VERSION ""

NS_ :

BS_:

BU_:
VAL_TABLE_ TAB_BattSimRemoteControl 3 "signal invalid" 2 "Remote-Control-Mode" 1 "Standalone-Mode" 0 "no signal" ;
VAL_TABLE_ TAB_BattSimOutputControl 3 "signal invalid" 2 "enable all outputs" 1 "disable all output" 0 "no signal" ;
VAL_TABLE_ TAB_BattSimOutputStatus 3 "signal invalid" 2 "Output enabled" 1 "Output disabled" 0 "no signal" ;
VAL_TABLE_ TAB_BattSimStatus 7 "signal invalid" 6 "reserved" 5 "FAIL" 4 "ON_DynamicCellSim" 3 "ON_RemoteControl" 2 "ON_Standalone" 1 "STANDBY" 0 "no signal" ;

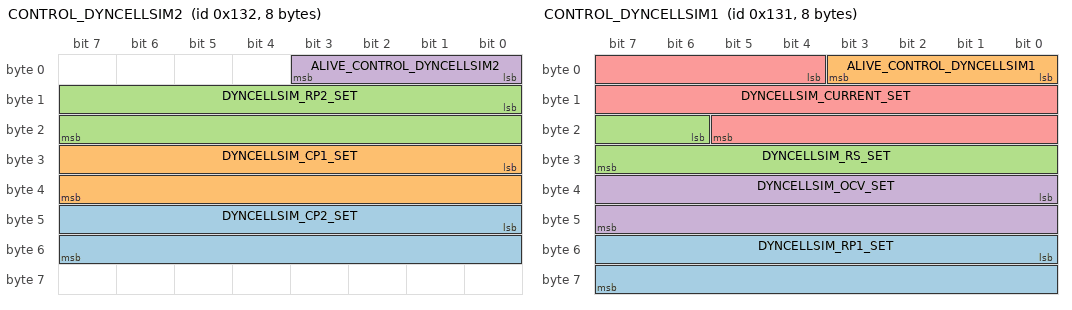
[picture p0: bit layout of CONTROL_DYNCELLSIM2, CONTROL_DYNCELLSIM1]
BO_ 306 CONTROL_DYNCELLSIM2: 8 Vector__XXX
 SG_ DYNCELLSIM_CP2_SET : 40|16@1+ (10,0) [0|655350] "F" Vector__XXX
 SG_ DYNCELLSIM_CP1_SET : 24|16@1+ (10,0) [0|655350] "F" Vector__XXX
 SG_ DYNCELLSIM_RP2_SET : 8|16@1+ (0.0001,0) [0|6.5535] "Ohm" Vector__XXX
 SG_ ALIVE_CONTROL_DYNCELLSIM2 : 0|4@1+ (1,0) [0|15] "" Vector__XXX

BO_ 305 CONTROL_DYNCELLSIM1: 8 Vector__XXX
 SG_ DYNCELLSIM_RP1_SET : 48|16@1+ (0.0001,0) [0|6.5535] "Ohm" Vector__XXX
 SG_ ALIVE_CONTROL_DYNCELLSIM1 : 0|4@1+ (1,0) [0|15] "" Vector__XXX
 SG_ DYNCELLSIM_RS_SET : 22|10@1+ (0.0001,0) [0|0.1023] "Ohm" Vector__XXX
 SG_ DYNCELLSIM_OCV_SET : 32|16@1+ (0.0001,0) [0|6.5535] "V" Vector__XXX
 SG_ DYNCELLSIM_CURRENT_SET : 4|18@1- (0.001,0) [-131.072|131.071] "A" Vector__XXX

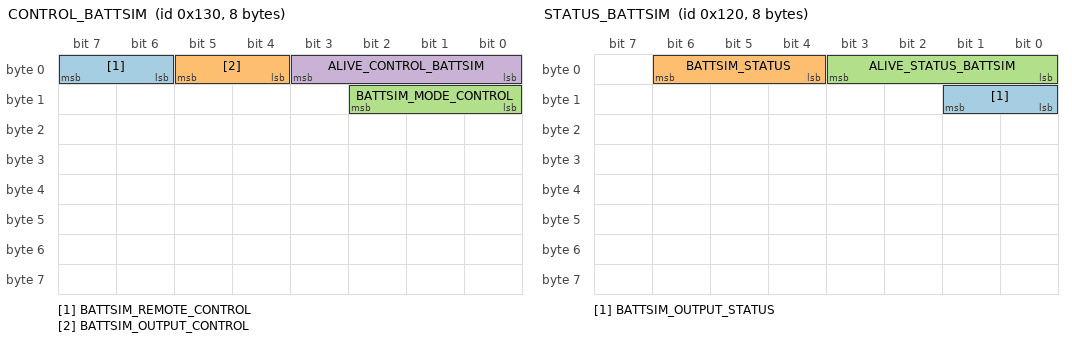
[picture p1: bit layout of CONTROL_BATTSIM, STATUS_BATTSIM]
BO_ 304 CONTROL_BATTSIM: 8 Vector__XXX
 SG_ BATTSIM_REMOTE_CONTROL : 6|2@1+ (1,0) [0|3] "" Vector__XXX
 SG_ BATTSIM_OUTPUT_CONTROL : 4|2@1+ (1,0) [0|3] "" Vector__XXX
 SG_ BATTSIM_MODE_CONTROL : 8|3@1+ (1,0) [0|7] "" Vector__XXX
 SG_ ALIVE_CONTROL_BATTSIM : 0|4@1+ (1,0) [0|15] "" Vector__XXX

BO_ 288 STATUS_BATTSIM: 8 Vector__XXX
 SG_ BATTSIM_OUTPUT_STATUS : 8|2@1+ (1,0) [0|3] "" Vector__XXX
 SG_ BATTSIM_STATUS : 4|3@1+ (1,0) [0|7] "" Vector__XXX
 SG_ ALIVE_STATUS_BATTSIM : 0|4@1+ (1,0) [0|15] "" Vector__XXX

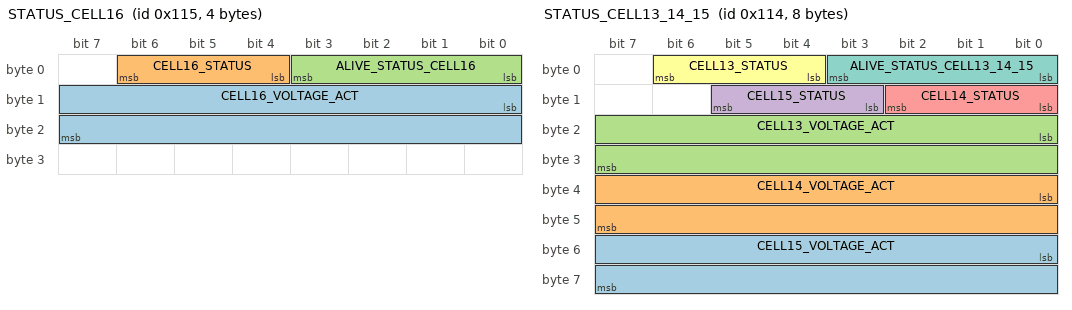
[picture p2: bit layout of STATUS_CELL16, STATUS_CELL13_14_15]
BO_ 277 STATUS_CELL16: 4 Vector__XXX
 SG_ CELL16_VOLTAGE_ACT : 8|16@1+ (0.0001,0) [0|6.5535] "V" Vector__XXX
 SG_ CELL16_STATUS : 4|3@1+ (1,0) [0|3] "" Vector__XXX
 SG_ ALIVE_STATUS_CELL16 : 0|4@1+ (1,0) [0|15] "" Vector__XXX

BO_ 276 STATUS_CELL13_14_15: 8 Vector__XXX
 SG_ CELL15_VOLTAGE_ACT : 48|16@1+ (0.0001,0) [0|6.5535] "V" Vector__XXX
 SG_ CELL14_VOLTAGE_ACT : 32|16@1+ (0.0001,0) [0|6.5535] "V" Vector__XXX
 SG_ CELL13_VOLTAGE_ACT : 16|16@1+ (0.0001,0) [0|6.5535] "V" Vector__XXX
 SG_ CELL15_STATUS : 11|3@1+ (1,0) [0|3] "" Vector__XXX
 SG_ CELL14_STATUS : 8|3@1+ (1,0) [0|3] "" Vector__XXX
 SG_ CELL13_STATUS : 4|3@1+ (1,0) [0|3] "" Vector__XXX
 SG_ ALIVE_STATUS_CELL13_14_15 : 0|4@1+ (1,0) [0|15] "" Vector__XXX

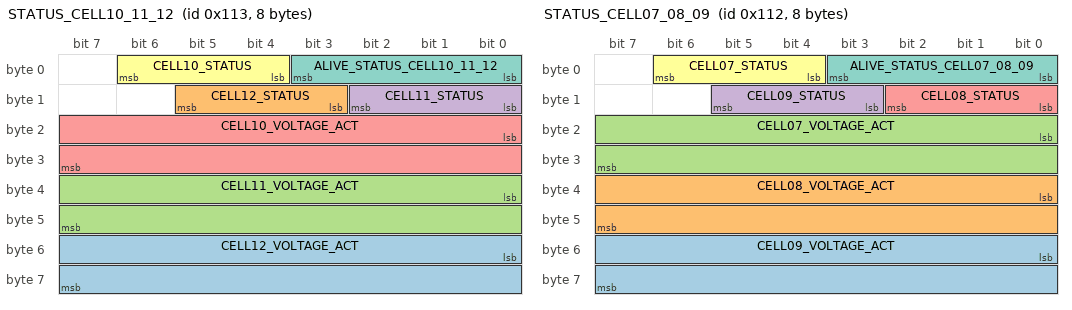
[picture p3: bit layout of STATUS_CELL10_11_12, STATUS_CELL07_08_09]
BO_ 275 STATUS_CELL10_11_12: 8 Vector__XXX
 SG_ CELL12_VOLTAGE_ACT : 48|16@1+ (0.0001,0) [0|6.5535] "V" Vector__XXX
 SG_ CELL12_STATUS : 11|3@1+ (1,0) [0|3] "" Vector__XXX
 SG_ CELL11_VOLTAGE_ACT : 32|16@1+ (0.0001,0) [0|6.5535] "V" Vector__XXX
 SG_ CELL11_STATUS : 8|3@1+ (1,0) [0|3] "" Vector__XXX
 SG_ CELL10_VOLTAGE_ACT : 16|16@1+ (0.0001,0) [0|6.5535] "V" Vector__XXX
 SG_ CELL10_STATUS : 4|3@1+ (1,0) [0|3] "" Vector__XXX
 SG_ ALIVE_STATUS_CELL10_11_12 : 0|4@1+ (1,0) [0|15] "" Vector__XXX

BO_ 274 STATUS_CELL07_08_09: 8 Vector__XXX
 SG_ CELL09_VOLTAGE_ACT : 48|16@1+ (0.0001,0) [0|6.5535] "V" Vector__XXX
 SG_ CELL08_VOLTAGE_ACT : 32|16@1+ (0.0001,0) [0|6.5535] "V" Vector__XXX
 SG_ CELL07_VOLTAGE_ACT : 16|16@1+ (0.0001,0) [0|6.5535] "V" Vector__XXX
 SG_ CELL09_STATUS : 11|3@1+ (1,0) [0|3] "" Vector__XXX
 SG_ CELL08_STATUS : 8|3@1+ (1,0) [0|3] "" Vector__XXX
 SG_ CELL07_STATUS : 4|3@1+ (1,0) [0|3] "" Vector__XXX
 SG_ ALIVE_STATUS_CELL07_08_09 : 0|4@1+ (1,0) [0|15] "" Vector__XXX

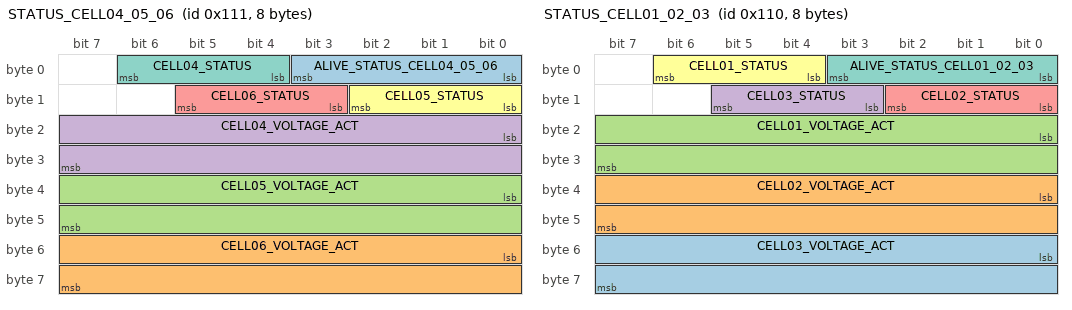
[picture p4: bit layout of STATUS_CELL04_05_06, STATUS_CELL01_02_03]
BO_ 273 STATUS_CELL04_05_06: 8 Vector__XXX
 SG_ ALIVE_STATUS_CELL04_05_06 : 0|4@1+ (1,0) [0|15] "" Vector__XXX
 SG_ CELL06_VOLTAGE_ACT : 48|16@1+ (0.0001,0) [0|6.5535] "V" Vector__XXX
 SG_ CELL05_VOLTAGE_ACT : 32|16@1+ (0.0001,0) [0|6.5535] "V" Vector__XXX
 SG_ CELL04_VOLTAGE_ACT : 16|16@1+ (0.0001,0) [0|6.5535] "V" Vector__XXX
 SG_ CELL06_STATUS : 11|3@1+ (1,0) [0|3] "" Vector__XXX
 SG_ CELL05_STATUS : 8|3@1+ (1,0) [0|3] "" Vector__XXX
 SG_ CELL04_STATUS : 4|3@1+ (1,0) [0|3] "" Vector__XXX

BO_ 272 STATUS_CELL01_02_03: 8 Vector__XXX
 SG_ CELL03_VOLTAGE_ACT : 48|16@1+ (0.0001,0) [0|6.5535] "V" Vector__XXX
 SG_ CELL02_VOLTAGE_ACT : 32|16@1+ (0.0001,0) [0|6.5535] "V" Vector__XXX
 SG_ CELL01_VOLTAGE_ACT : 16|16@1+ (0.0001,0) [0|6.5535] "V" Vector__XXX
 SG_ CELL03_STATUS : 11|3@1+ (1,0) [0|3] "" Vector__XXX
 SG_ CELL02_STATUS : 8|3@1+ (1,0) [0|3] "" Vector__XXX
 SG_ CELL01_STATUS : 4|3@1+ (1,0) [0|3] "" Vector__XXX
 SG_ ALIVE_STATUS_CELL01_02_03 : 0|4@1+ (1,0) [0|15] "" Vector__XXX

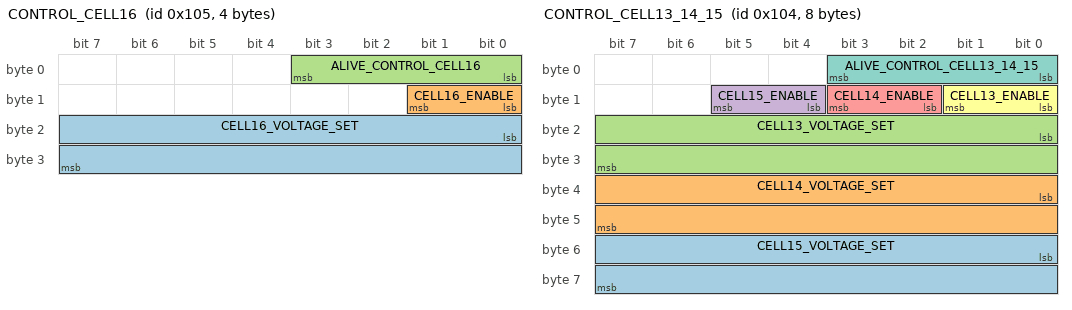
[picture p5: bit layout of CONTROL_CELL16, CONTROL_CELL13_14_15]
BO_ 261 CONTROL_CELL16: 4 Vector__XXX
 SG_ CELL16_VOLTAGE_SET : 16|16@1+ (0.0001,0) [0|6.5535] "V" Vector__XXX
 SG_ CELL16_ENABLE : 8|2@1+ (1,0) [0|3] "" Vector__XXX
 SG_ ALIVE_CONTROL_CELL16 : 0|4@1+ (1,0) [0|15] "" Vector__XXX

BO_ 260 CONTROL_CELL13_14_15: 8 Vector__XXX
 SG_ CELL15_VOLTAGE_SET : 48|16@1+ (0.0001,0) [0|6.5535] "V" Vector__XXX
 SG_ CELL14_VOLTAGE_SET : 32|16@1+ (0.0001,0) [0|6.5535] "V" Vector__XXX
 SG_ CELL13_VOLTAGE_SET : 16|16@1+ (0.0001,0) [0|6.5535] "V" Vector__XXX
 SG_ CELL15_ENABLE : 12|2@1+ (1,0) [0|3] "" Vector__XXX
 SG_ CELL14_ENABLE : 10|2@1+ (1,0) [0|3] "" Vector__XXX
 SG_ CELL13_ENABLE : 8|2@1+ (1,0) [0|3] "" Vector__XXX
 SG_ ALIVE_CONTROL_CELL13_14_15 : 0|4@1+ (1,0) [0|15] "" Vector__XXX

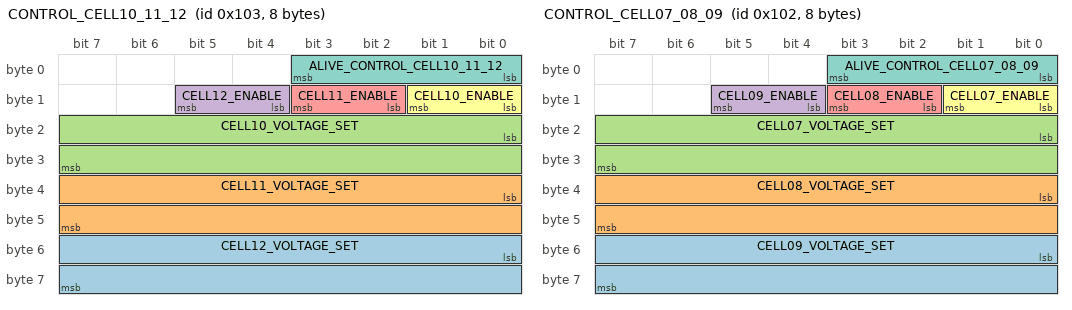
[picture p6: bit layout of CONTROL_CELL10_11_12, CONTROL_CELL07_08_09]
BO_ 259 CONTROL_CELL10_11_12: 8 Vector__XXX
 SG_ CELL12_VOLTAGE_SET : 48|16@1+ (0.0001,0) [0|6.5535] "V" Vector__XXX
 SG_ CELL11_VOLTAGE_SET : 32|16@1+ (0.0001,0) [0|6.5535] "V" Vector__XXX
 SG_ CELL10_VOLTAGE_SET : 16|16@1+ (0.0001,0) [0|6.5535] "V" Vector__XXX
 SG_ CELL12_ENABLE : 12|2@1+ (1,0) [0|3] "" Vector__XXX
 SG_ CELL11_ENABLE : 10|2@1+ (1,0) [0|3] "" Vector__XXX
 SG_ CELL10_ENABLE : 8|2@1+ (1,0) [0|3] "" Vector__XXX
 SG_ ALIVE_CONTROL_CELL10_11_12 : 0|4@1+ (1,0) [0|15] "" Vector__XXX

BO_ 258 CONTROL_CELL07_08_09: 8 Vector__XXX
 SG_ CELL09_VOLTAGE_SET : 48|16@1+ (0.0001,0) [0|6.5535] "V" Vector__XXX
 SG_ CELL08_VOLTAGE_SET : 32|16@1+ (0.0001,0) [0|6.5535] "V" Vector__XXX
 SG_ CELL07_VOLTAGE_SET : 16|16@1+ (0.0001,0) [0|6.5535] "V" Vector__XXX
 SG_ CELL09_ENABLE : 12|2@1+ (1,0) [0|3] "" Vector__XXX
 SG_ CELL08_ENABLE : 10|2@1+ (1,0) [0|3] "" Vector__XXX
 SG_ CELL07_ENABLE : 8|2@1+ (1,0) [0|3] "" Vector__XXX
 SG_ ALIVE_CONTROL_CELL07_08_09 : 0|4@1+ (1,0) [0|15] "" Vector__XXX

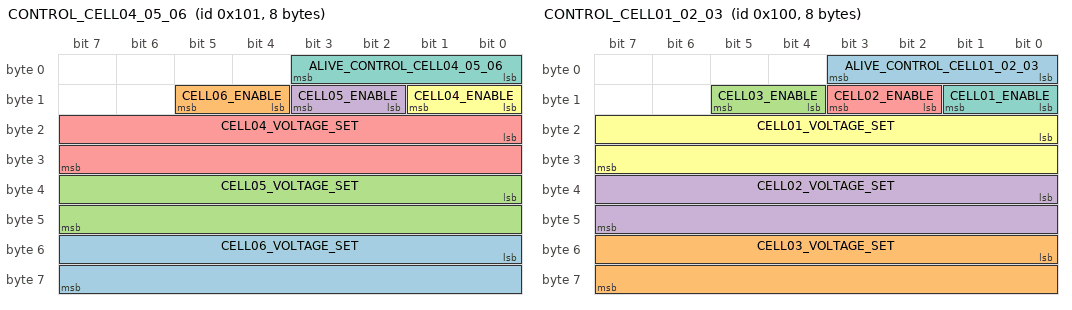
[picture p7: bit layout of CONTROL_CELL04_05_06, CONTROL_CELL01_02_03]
BO_ 257 CONTROL_CELL04_05_06: 8 Vector__XXX
 SG_ CELL06_VOLTAGE_SET : 48|16@1+ (0.0001,0) [0|6.5535] "V" Vector__XXX
 SG_ CELL06_ENABLE : 12|2@1+ (1,0) [0|3] "" Vector__XXX
 SG_ CELL05_VOLTAGE_SET : 32|16@1+ (0.0001,0) [0|6.5535] "V" Vector__XXX
 SG_ CELL05_ENABLE : 10|2@1+ (1,0) [0|3] "" Vector__XXX
 SG_ CELL04_VOLTAGE_SET : 16|16@1+ (0.0001,0) [0|6.5535] "V" Vector__XXX
 SG_ CELL04_ENABLE : 8|2@1+ (1,0) [0|3] "" Vector__XXX
 SG_ ALIVE_CONTROL_CELL04_05_06 : 0|4@1+ (1,0) [0|15] "" Vector__XXX

BO_ 256 CONTROL_CELL01_02_03: 8 Vector__XXX
 SG_ ALIVE_CONTROL_CELL01_02_03 : 0|4@1+ (1,0) [0|15] "" Vector__XXX
 SG_ CELL03_VOLTAGE_SET : 48|16@1+ (0.0001,0) [0|6.5535] "V" Vector__XXX
 SG_ CELL03_ENABLE : 12|2@1+ (1,0) [0|3] "" Vector__XXX
 SG_ CELL02_VOLTAGE_SET : 32|16@1+ (0.0001,0) [0|6.5535] "V" Vector__XXX
 SG_ CELL02_ENABLE : 10|2@1+ (1,0) [0|3] "" Vector__XXX
 SG_ CELL01_VOLTAGE_SET : 16|16@1+ (0.0001,0) [0|6.5535] "V" Vector__XXX
 SG_ CELL01_ENABLE : 8|2@1+ (1,0) [0|3] "" Vector__XXX

CM_ SG_ 305 DYNCELLSIM_OCV_SET "Zellspannungs-Vorgabe";
CM_ SG_ 277 CELL16_VOLTAGE_ACT "gemessene Zellspannung 16";
CM_ SG_ 276 CELL15_VOLTAGE_ACT "gemessene Zellspannung 15";
CM_ SG_ 276 CELL14_VOLTAGE_ACT "gemessene Zellspannung 14";
CM_ SG_ 276 CELL13_VOLTAGE_ACT "gemessene Zellspannung 13";
CM_ SG_ 275 CELL12_VOLTAGE_ACT "gemessene Zellspannung 12";
CM_ SG_ 275 CELL11_VOLTAGE_ACT "gemessene Zellspannung 11";
CM_ SG_ 275 CELL10_VOLTAGE_ACT "gemessene Zellspannung 10";
CM_ SG_ 274 CELL09_VOLTAGE_ACT "gemessene Zellspannung 9";
CM_ SG_ 274 CELL08_VOLTAGE_ACT "gemessene Zellspannung 8";
CM_ SG_ 274 CELL07_VOLTAGE_ACT "gemessene Zellspannung 7";
CM_ SG_ 273 CELL06_VOLTAGE_ACT "gemessene Zellspannung 6";
CM_ SG_ 273 CELL05_VOLTAGE_ACT "gemessene Zellspannung 5";
CM_ SG_ 273 CELL04_VOLTAGE_ACT "gemessene Zellspannung 4";
CM_ SG_ 272 CELL03_VOLTAGE_ACT "gemessene Zellspannung 3";
CM_ SG_ 272 CELL02_VOLTAGE_ACT "gemessene Zellspannung 2";
CM_ SG_ 272 CELL01_VOLTAGE_ACT "gemessene Zellspannung 1";
CM_ SG_ 261 CELL16_VOLTAGE_SET "Zellspannungs-Vorgabe 16";
CM_ SG_ 260 CELL15_VOLTAGE_SET "Zellspannungs-Vorgabe 15";
CM_ SG_ 260 CELL14_VOLTAGE_SET "Zellspannungs-Vorgabe";
CM_ SG_ 260 CELL13_VOLTAGE_SET "Zellspannungs-Vorgabe";
CM_ SG_ 259 CELL12_VOLTAGE_SET "Zellspannungs-Vorgabe";
CM_ SG_ 259 CELL11_VOLTAGE_SET "Zellspannungs-Vorgabe";
CM_ SG_ 259 CELL10_VOLTAGE_SET "Zellspannungs-Vorgabe";
CM_ SG_ 258 CELL09_VOLTAGE_SET "Zellspannungs-Vorgabe";
CM_ SG_ 258 CELL08_VOLTAGE_SET "Zellspannungs-Vorgabe";
CM_ SG_ 258 CELL07_VOLTAGE_SET "Zellspannungs-Vorgabe";
CM_ SG_ 257 CELL06_VOLTAGE_SET "Zellspannungs-Vorgabe";
CM_ SG_ 257 CELL05_VOLTAGE_SET "Zellspannungs-Vorgabe";
CM_ SG_ 257 CELL04_VOLTAGE_SET "Zellspannungs-Vorgabe";
CM_ SG_ 256 CELL03_VOLTAGE_SET "Zellspannungs-Vorgabe";
CM_ SG_ 256 CELL02_VOLTAGE_SET "Zellspannungs-Vorgabe";
CM_ SG_ 256 CELL01_VOLTAGE_SET "Zellspannungs-Vorgabe";
BA_DEF_  "BusType" STRING ;
BA_DEF_DEF_  "BusType" "CAN";
VAL_ 304 BATTSIM_REMOTE_CONTROL 3 "signal invalid" 2 "Remote-Control-Mode" 1 "Standalone-Mode" 0 "no signal" ;
VAL_ 304 BATTSIM_OUTPUT_CONTROL 3 "signal invalid" 2 "enable all outputs" 1 "disable all output" 0 "no signal" ;
VAL_ 304 BATTSIM_MODE_CONTROL 7 "signal invalid" 3 "DYNAMIC_CELL_SIM" 2 "ON" 1 "STANDBY" 0 "no value" ;
VAL_ 288 BATTSIM_OUTPUT_STATUS 3 "signal invalid" 2 "Output enabled" 1 "Output disabled" 0 "no signal" ;
VAL_ 288 BATTSIM_STATUS 7 "signal invalid" 6 "reserved" 5 "FAIL" 4 "ON_DynamicCellSim" 3 "ON_RemoteControl" 2 "ON_Standalone" 1 "STANDBY" 0 "no signal" ;
VAL_ 277 CELL16_STATUS 7 "signal invalid" 6 "reserved" 5 "reserved" 4 "reserved" 3 "setpoint error" 2 "enabled" 1 "disabled" 0 "no value" ;
VAL_ 276 CELL15_STATUS 7 "signal invalid" 6 "reserved" 5 "reserved" 4 "reserved" 3 "setpoint error" 2 "enabled" 1 "disabled" 0 "no value" ;
VAL_ 276 CELL14_STATUS 7 "signal invalid" 6 "reserved" 5 "reserved" 4 "reserved" 3 "setpoint error" 2 "enabled" 1 "disabled" 0 "no value" ;
VAL_ 276 CELL13_STATUS 7 "signal invalid" 6 "reserved" 5 "reserved" 4 "reserved" 3 "setpoint error" 2 "enabled" 1 "disabled" 0 "no value" ;
VAL_ 275 CELL12_STATUS 7 "signal invalid" 6 "reserved" 5 "reserved" 4 "reserved" 3 "setpoint error" 2 "enabled" 1 "disabled" 0 "no value" ;
VAL_ 275 CELL11_STATUS 7 "signal invalid" 6 "reserved" 5 "reserved" 4 "reserved" 3 "setpoint error" 2 "enabled" 1 "disabled" 0 "no value" ;
VAL_ 275 CELL10_STATUS 7 "signal invalid" 6 "reserved" 5 "reserved" 4 "reserved" 3 "setpoint error" 2 "enabled" 1 "disabled" 0 "no value" ;
VAL_ 274 CELL09_STATUS 7 "signal invalid" 6 "reserved" 5 "reserved" 4 "reserved" 3 "setpoint error" 2 "enabled" 1 "disabled" 0 "no value" ;
VAL_ 274 CELL08_STATUS 7 "signal invalid" 6 "reserved" 5 "reserved" 4 "reserved" 3 "setpoint error" 2 "enabled" 1 "disabled" 0 "no value" ;
VAL_ 274 CELL07_STATUS 7 "signal invalid" 6 "reserved" 5 "reserved" 4 "reserved" 3 "setpoint error" 2 "enabled" 1 "disabled" 0 "no value" ;
VAL_ 273 CELL06_STATUS 7 "signal invalid" 6 "reserved" 5 "reserved" 4 "reserved" 3 "setpoint error" 2 "enabled" 1 "disabled" 0 "no value" ;
VAL_ 273 CELL05_STATUS 7 "signal invalid" 6 "reserved" 5 "reserved" 4 "reserved" 3 "setpoint error" 2 "enabled" 1 "disabled" 0 "no value" ;
VAL_ 273 CELL04_STATUS 7 "signal invalid" 6 "reserved" 5 "reserved" 4 "reserved" 3 "setpoint error" 2 "enabled" 1 "disabled" 0 "no value" ;
VAL_ 272 CELL03_STATUS 7 "signal invalid" 6 "reserved" 5 "reserved" 4 "reserved" 3 "setpoint error" 2 "enabled" 1 "disabled" 0 "no value" ;
VAL_ 272 CELL02_STATUS 7 "signal invalid" 6 "reserved" 5 "reserved" 4 "reserved" 3 "setpoint error" 2 "enabled" 1 "disabled" 0 "no value" ;
VAL_ 272 CELL01_STATUS 7 "signal invalid" 6 "reserved" 5 "reserved" 4 "reserved" 3 "setpoint error" 2 "enabled" 1 "disabled" 0 "no value" ;
VAL_ 261 CELL16_ENABLE 3 "signal invalid" 2 "enable" 1 "disable" 0 "no value" ;
VAL_ 260 CELL15_ENABLE 3 "signal invalid" 2 "enable" 1 "disable" 0 "no value" ;
VAL_ 260 CELL14_ENABLE 3 "signal invalid" 2 "enable" 1 "disable" 0 "no value" ;
VAL_ 260 CELL13_ENABLE 3 "signal invalid" 2 "enable" 1 "disable" 0 "no value" ;
VAL_ 259 CELL12_ENABLE 3 "signal invalid" 2 "enable" 1 "disable" 0 "no value" ;
VAL_ 259 CELL11_ENABLE 3 "signal invalid" 2 "enable" 1 "disable" 0 "no value" ;
VAL_ 259 CELL10_ENABLE 3 "signal invalid" 2 "enable" 1 "disable" 0 "no value" ;
VAL_ 258 CELL09_ENABLE 3 "signal invalid" 2 "enable" 1 "disable" 0 "no value" ;
VAL_ 258 CELL08_ENABLE 3 "signal invalid" 2 "enable" 1 "disable" 0 "no value" ;
VAL_ 258 CELL07_ENABLE 3 "signal invalid" 2 "enable" 1 "disable" 0 "no value" ;
VAL_ 257 CELL06_ENABLE 3 "signal invalid" 2 "enable" 1 "disable" 0 "no value" ;
VAL_ 257 CELL05_ENABLE 3 "signal invalid" 2 "enable" 1 "disable" 0 "no value" ;
VAL_ 257 CELL04_ENABLE 3 "signal invalid" 2 "enable" 1 "disable" 0 "no value" ;
VAL_ 256 CELL03_ENABLE 3 "signal invalid" 2 "enable" 1 "disable" 0 "no value" ;
VAL_ 256 CELL02_ENABLE 3 "signal invalid" 2 "enable" 1 "disable" 0 "no value" ;
VAL_ 256 CELL01_ENABLE 3 "signal invalid" 2 "enable" 1 "disable" 0 "no value" ;
